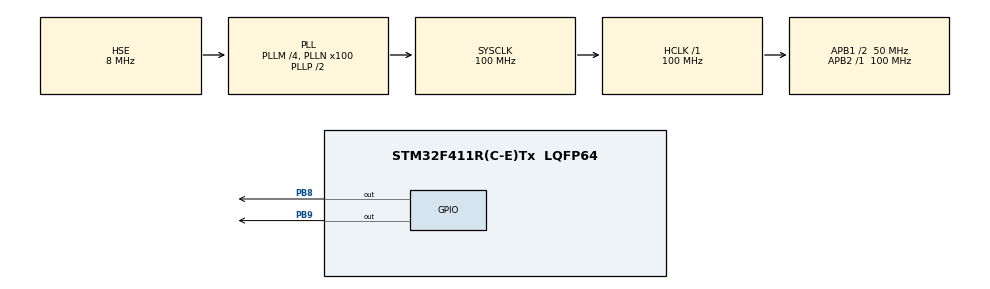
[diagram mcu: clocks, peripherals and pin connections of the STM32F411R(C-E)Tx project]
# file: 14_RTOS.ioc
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FREERTOS.Tasks01=LED2,24,128,LED_2,Default,NULL,Dynamic,NULL,NULL;LED1,8,128,LED_1,Default,NULL,Dynamic,NULL,NULL
FREERTOS.configUSE_NEWLIB_REENTRANT=1
Mcu.Family=STM32F4
Mcu.Name=STM32F411R(C-E)Tx
Mcu.Package=LQFP64
NVIC.PriorityGroup=NVIC_PRIORITYGROUP_4
NVIC.TIM1_TRG_COM_TIM11_IRQn=true\:15\:0\:false\:false\:true\:false\:false\:true\:true
NVIC.TimeBase=TIM1_TRG_COM_TIM11_IRQn
NVIC.TimeBaseIP=TIM11
PA13.Mode=Serial_Wire
PA13.Signal=SYS_JTMS-SWDIO
PA14.Mode=Serial_Wire
PA14.Signal=SYS_JTCK-SWCLK
PB8.Signal=GPIO_Output
PB9.Signal=GPIO_Output
PH0\ -\ OSC_IN.Mode=HSE-External-Oscillator
PH0\ -\ OSC_IN.Signal=RCC_OSC_IN
PH1\ -\ OSC_OUT.Mode=HSE-External-Oscillator
PH1\ -\ OSC_OUT.Signal=RCC_OSC_OUT
ProjectManager.HeapSize=0x200
ProjectManager.StackSize=0x400
ProjectManager.TargetToolchain=STM32CubeIDE
RCC.48MHZClocksFreq_Value=50000000
RCC.AHBFreq_Value=100000000
RCC.APB1CLKDivider=RCC_HCLK_DIV2
RCC.APB1Freq_Value=50000000
RCC.APB1TimFreq_Value=100000000
RCC.APB2Freq_Value=100000000
RCC.APB2TimFreq_Value=100000000
RCC.CortexFreq_Value=100000000
RCC.HCLKFreq_Value=100000000
RCC.HSE_VALUE=8000000
RCC.HSI_VALUE=16000000
RCC.LSE_VALUE=32768
RCC.PLLM=4
RCC.PLLN=100
RCC.PLLSourceVirtual=RCC_PLLSOURCE_HSE
RCC.SYSCLKFreq_VALUE=100000000
RCC.SYSCLKSource=RCC_SYSCLKSOURCE_PLLCLK
RCC.VCOOutputFreq_Value=200000000
VP_FREERTOS_VS_CMSIS_V2.Mode=CMSIS_V2
VP_SYS_VS_tim11.Mode=TIM11
board=custom

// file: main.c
/* USER CODE BEGIN Header */
/**
  ******************************************************************************
  * @file           : main.c
  * @brief          : Main program body
  ******************************************************************************
  * @attention
  *
  * Copyright (c) 2025 STMicroelectronics.
  * All rights reserved.
  *
  * This software is licensed under terms that can be found in the LICENSE file
  * in the root directory of this software component.
  * If no LICENSE file comes with this software, it is provided AS-IS.
  *
  ******************************************************************************
  */
/* USER CODE END Header */
#include "main.h"
#include "cmsis_os.h"
#include "gpio.h"

void SystemClock_Config(void);
void MX_FREERTOS_Init(void);

int main(void)
{

  /* MCU Configuration--------------------------------------------------------*/

  /* Reset of all peripherals, Initializes the Flash interface and the Systick. */
  HAL_Init();

  /* Configure the system clock */
  SystemClock_Config();

  /* Initialize all configured peripherals */
  MX_GPIO_Init();

  /* Init scheduler */
  osKernelInitialize();

  /* Call init function for freertos objects (in cmsis_os2.c) */
  MX_FREERTOS_Init();

  /* Start scheduler */
  osKernelStart();

  /* We should never get here as control is now taken by the scheduler */

  /* Infinite loop */
  /* USER CODE BEGIN WHILE */
  while (1)
  {
	  HAL_GPIO_WritePin(GPIOB, GPIO_PIN_8, 1);
	  HAL_Delay(500);
	  HAL_GPIO_WritePin(GPIOB, GPIO_PIN_8, 0);
	  HAL_Delay(500);

	  HAL_GPIO_WritePin(GPIOB, GPIO_PIN_9, 1);
	  HAL_Delay(1000);
	  HAL_GPIO_WritePin(GPIOB, GPIO_PIN_9, 0);
	  HAL_Delay(1000);

    /* USER CODE END WHILE */

  }
}

void SystemClock_Config(void)
{
  RCC_OscInitTypeDef RCC_OscInitStruct = {0};
  RCC_ClkInitTypeDef RCC_ClkInitStruct = {0};

  /** Configure the main internal regulator output voltage
  */
  __HAL_RCC_PWR_CLK_ENABLE();
  __HAL_PWR_VOLTAGESCALING_CONFIG(PWR_REGULATOR_VOLTAGE_SCALE1);

  /** Initializes the RCC Oscillators according to the specified parameters
  * in the RCC_OscInitTypeDef structure.
  */
  RCC_OscInitStruct.OscillatorType = RCC_OSCILLATORTYPE_HSE;
  RCC_OscInitStruct.HSEState = RCC_HSE_ON;
  RCC_OscInitStruct.PLL.PLLState = RCC_PLL_ON;
  RCC_OscInitStruct.PLL.PLLSource = RCC_PLLSOURCE_HSE;
  RCC_OscInitStruct.PLL.PLLM = 4;
  RCC_OscInitStruct.PLL.PLLN = 100;
  RCC_OscInitStruct.PLL.PLLP = RCC_PLLP_DIV2;
  RCC_OscInitStruct.PLL.PLLQ = 4;
  if (HAL_RCC_OscConfig(&RCC_OscInitStruct) != HAL_OK)
  {
    Error_Handler();
  }

  /** Initializes the CPU, AHB and APB buses clocks
  */
  RCC_ClkInitStruct.ClockType = RCC_CLOCKTYPE_HCLK|RCC_CLOCKTYPE_SYSCLK
                              |RCC_CLOCKTYPE_PCLK1|RCC_CLOCKTYPE_PCLK2;
  RCC_ClkInitStruct.SYSCLKSource = RCC_SYSCLKSOURCE_PLLCLK;
  RCC_ClkInitStruct.AHBCLKDivider = RCC_SYSCLK_DIV1;
  RCC_ClkInitStruct.APB1CLKDivider = RCC_HCLK_DIV2;
  RCC_ClkInitStruct.APB2CLKDivider = RCC_HCLK_DIV1;

  if (HAL_RCC_ClockConfig(&RCC_ClkInitStruct, FLASH_LATENCY_3) != HAL_OK)
  {
    Error_Handler();
  }
}

void HAL_TIM_PeriodElapsedCallback(TIM_HandleTypeDef *htim)
{
  if (htim->Instance == TIM11)
  {
    HAL_IncTick();
  }
}

void Error_Handler(void)
{
  __disable_irq();
  while (1)
  {
  }
}

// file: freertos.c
/* USER CODE BEGIN Header */
/**
  ******************************************************************************
  * File Name          : freertos.c
  * Description        : Code for freertos applications
  ******************************************************************************
  * @attention
  *
  * Copyright (c) 2025 STMicroelectronics.
  * All rights reserved.
  *
  * This software is licensed under terms that can be found in the LICENSE file
  * in the root directory of this software component.
  * If no LICENSE file comes with this software, it is provided AS-IS.
  *
  ******************************************************************************
  */
/* USER CODE END Header */

#include "FreeRTOS.h"
#include "task.h"
#include "main.h"
#include "cmsis_os.h"

/* Definitions for LED2 */
osThreadId_t LED2Handle;
const osThreadAttr_t LED2_attributes = {
  .name = "LED2",
  .stack_size = 128 * 4,
  .priority = (osPriority_t) osPriorityNormal,
};
/* Definitions for LED1 */
osThreadId_t LED1Handle;
const osThreadAttr_t LED1_attributes = {
  .name = "LED1",
  .stack_size = 128 * 4,
  .priority = (osPriority_t) osPriorityLow,
};

void LED_2(void *argument);
void LED_1(void *argument);

void MX_FREERTOS_Init(void); /* (MISRA C 2004 rule 8.1) */

void MX_FREERTOS_Init(void) {

  /* Create the thread(s) */
  /* creation of LED2 */
  LED2Handle = osThreadNew(LED_2, NULL, &LED2_attributes);

  /* creation of LED1 */
  LED1Handle = osThreadNew(LED_1, NULL, &LED1_attributes);

}

void LED_2(void *argument)
{
  /* USER CODE BEGIN LED_2 */
  /* Infinite loop */
  for(;;)
  {
	  HAL_GPIO_WritePin(GPIOB, GPIO_PIN_9, 1);
	  HAL_Delay(500);
	  HAL_GPIO_WritePin(GPIOB, GPIO_PIN_9, 0);
	  HAL_Delay(500);
	  osDelay(1);

  }
  /* USER CODE END LED_2 */
}

void LED_1(void *argument)
{
  /* USER CODE BEGIN LED_1 */
  /* Infinite loop */
  for(;;)
  {
	  HAL_GPIO_WritePin(GPIOB, GPIO_PIN_8, 1);
	  HAL_Delay(1000);
	  HAL_GPIO_WritePin(GPIOB, GPIO_PIN_8, 0);
	  HAL_Delay(1000);
	  osDelay(1);

  }
  /* USER CODE END LED_1 */
}
